# STM32F407VG register map
Vendor: STMicroelectronics
CPU: CM4
Registers are 32-bit, access not given, reset 0x0 unless marked. A register's access mark holds for its fields unless they carry their own. Offsets are from the block's base; lines under a group give offsets from that group; [hi:lo] are bit positions; {n}, {i} and the like mark numbered series; 'fields as' and 'values as' point back to an identical list; <NAME> marks a mode.

## Memory map
0x40000000 TIM2 — General purpose timer
0x40011000 USART1 — Universal synchronous/asynchronous receiver/transmitter
0x40020000 GPIOA — General purpose I/O A
0x40020400 GPIOB — General purpose I/O B
0x40020800 GPIOC — General purpose I/O C
0x40020C00 GPIOD — General purpose I/O D
0x40021000 GPIOE — General purpose I/O E
0x40023800 RCC — Reset and clock control

## RCC — Reset and clock control
Base 0x40023800
0x00 CR — Clock control
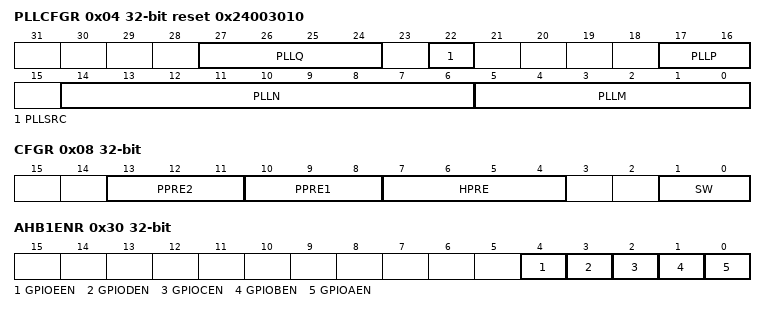
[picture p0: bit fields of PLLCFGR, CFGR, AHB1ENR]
0x04 PLLCFGR reset 0x24003010 — PLL configuration
  [27:24] PLLQ, [22] PLLSRC, [17:16] PLLP, [14:6] PLLN, [5:0] PLLM
0x08 CFGR — Clock configuration
  [13:11] PPRE2, [10:8] PPRE1, [7:4] HPRE, [1:0] SW
0x30 AHB1ENR — AHB1 peripheral clock enable
  [4] GPIOEEN, [3] GPIODEN, [2] GPIOCEN, [1] GPIOBEN, [0] GPIOAEN
0x40 APB1ENR — APB1 peripheral clock enable
0x44 APB2ENR — APB2 peripheral clock enable

## GPIOA — General purpose I/O A
Base 0x40020000
0x00 MODER reset 0xA8000000 — Mode
0x04 OTYPER — Output type
0x08 OSPEEDR — Output speed
0x0C PUPDR — Pull-up/pull-down
0x10 IDR — Input data
0x14 ODR — Output data
0x18 BSRR — Bit set/reset
0x20 AFRL — Alternate function low (pins 0-7)
0x24 AFRH — Alternate function high (pins 8-15)

## GPIOB — General purpose I/O B
Base 0x40020400
Same registers: GPIOC 0x40020800, GPIOD 0x40020C00, GPIOE 0x40021000
Registers as GPIOA; these are added or differ:
0x00 MODER — Mode

## USART1 — Universal synchronous/asynchronous receiver/transmitter
Base 0x40011000
0x00 SR — Status
0x04 DR — Data
0x08 BRR — Baud rate
0x0C CR1 — Control 1

## TIM2 — General purpose timer
Base 0x40000000
0x00 CR1 — Control 1
0x24 CNT — Counter
0x28 PSC — Prescaler
0x2C ARR — Auto-reload
